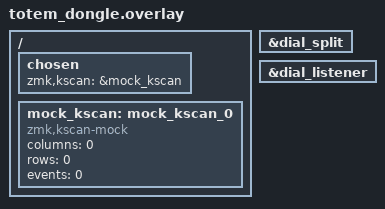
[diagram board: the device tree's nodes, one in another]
/* SPDX-License-Identifier: MIT */

#include "totem.dtsi"

/ {
    chosen {
        zmk,kscan = &mock_kscan;
    };

    mock_kscan: mock_kscan_0 {
        compatible = "zmk,kscan-mock";
        columns = <0>;
        rows = <0>;
        events = <0>;
    };
};

&dial_split {
    status = "okay";
};

&dial_listener {
    status = "okay";
};
